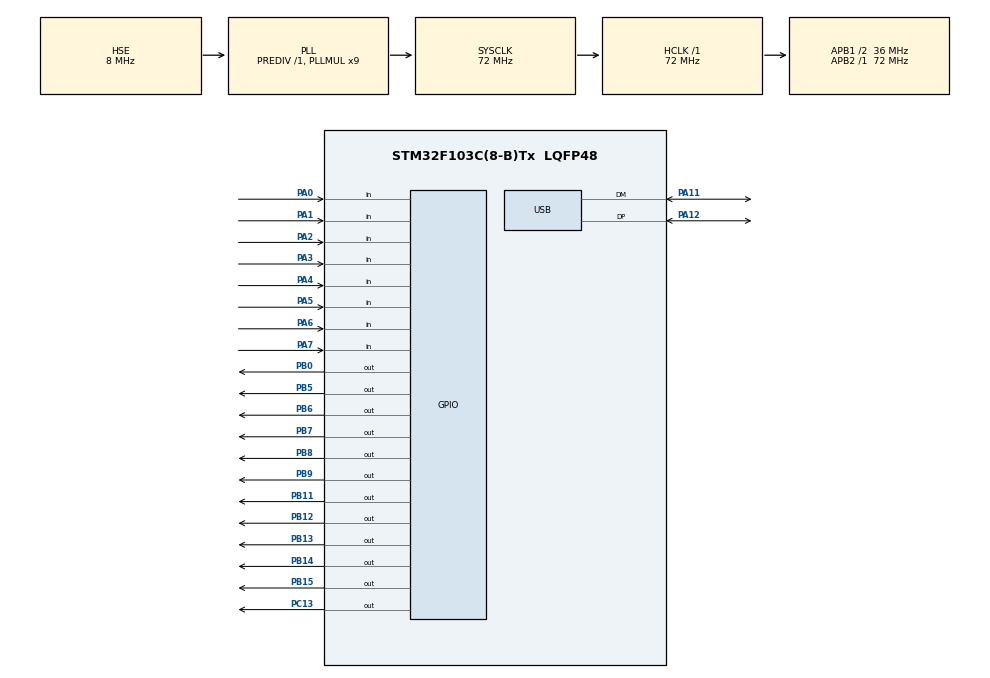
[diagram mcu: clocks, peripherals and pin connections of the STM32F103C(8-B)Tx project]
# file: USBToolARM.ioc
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Mcu.Family=STM32F1
Mcu.Name=STM32F103C(8-B)Tx
Mcu.Package=LQFP48
NVIC.PriorityGroup=NVIC_PRIORITYGROUP_4
NVIC.USB_LP_CAN1_RX0_IRQn=true\:0\:0\:false\:false\:true\:false\:true\:true
PA0-WKUP.Signal=GPIO_Input
PA1.Signal=GPIO_Input
PA11.Mode=Device
PA11.Signal=USB_DM
PA12.Mode=Device
PA12.Signal=USB_DP
PA2.Signal=GPIO_Input
PA3.Signal=GPIO_Input
PA4.Signal=GPIO_Input
PA5.Signal=GPIO_Input
PA6.Signal=GPIO_Input
PA7.Signal=GPIO_Input
PB0.GPIO_Speed=GPIO_SPEED_FREQ_HIGH
PB0.Signal=GPIO_Output
PB11.PinState=GPIO_PIN_SET
PB11.Signal=GPIO_Output
PB12.PinState=GPIO_PIN_RESET
PB12.Signal=GPIO_Output
PB13.Signal=GPIO_Output
PB14.Signal=GPIO_Output
PB15.Signal=GPIO_Output
PB5.GPIO_Speed=GPIO_SPEED_FREQ_HIGH
PB5.Signal=GPIO_Output
PB6.GPIO_PuPd=GPIO_NOPULL
PB6.GPIO_Speed=GPIO_SPEED_FREQ_HIGH
PB6.Signal=GPIO_Output
PB7.GPIO_Speed=GPIO_SPEED_FREQ_HIGH
PB7.Signal=GPIO_Output
PB8.GPIO_Speed=GPIO_SPEED_FREQ_HIGH
PB8.Signal=GPIO_Output
PB9.GPIO_Speed=GPIO_SPEED_FREQ_HIGH
PB9.Signal=GPIO_Output
PC13-TAMPER-RTC.GPIO_ModeDefaultOutputPP=GPIO_MODE_OUTPUT_PP
PC13-TAMPER-RTC.GPIO_PuPd=GPIO_PULLUP
PC13-TAMPER-RTC.Signal=GPIO_Output
PD0-OSC_IN.Mode=HSE-External-Oscillator
PD0-OSC_IN.Signal=RCC_OSC_IN
PD1-OSC_OUT.Mode=HSE-External-Oscillator
PD1-OSC_OUT.Signal=RCC_OSC_OUT
ProjectManager.HeapSize=0x200
ProjectManager.StackSize=0x400
ProjectManager.TargetToolchain=STM32CubeIDE
RCC.AHBFreq_Value=72000000
RCC.APB1CLKDivider=RCC_HCLK_DIV2
RCC.APB1Freq_Value=36000000
RCC.APB1TimFreq_Value=72000000
RCC.APB2Freq_Value=72000000
RCC.APB2TimFreq_Value=72000000
RCC.EnbaleCSS=true
RCC.HCLKFreq_Value=72000000
RCC.PLLMUL=RCC_PLL_MUL9
RCC.PLLSourceVirtual=RCC_PLLSOURCE_HSE
RCC.SYSCLKFreq_VALUE=72000000
RCC.SYSCLKSource=RCC_SYSCLKSOURCE_PLLCLK
RCC.USBFreq_Value=48000000
RCC.USBPrescaler=RCC_USBCLKSOURCE_PLL_DIV1_5
TIM1.Period=0xffff-1
TIM1.Prescaler=72-1
USB_DEVICE.CLASS_NAME_FS=CUSTOM_HID
USB_DEVICE.PID_CUSTOMHID_FS=0x0052
USB_DEVICE.VID=0x04d8
USB_DEVICE.VirtualMode=CustomHid
USB_DEVICE.VirtualModeFS=Custom_Hid_FS
VP_TIM1_VS_ClockSourceINT.Mode=Internal
VP_USB_DEVICE_VS_USB_DEVICE_CUSTOM_HID_FS.Mode=CUSTOM_HID_FS
board=custom

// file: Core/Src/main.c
/* USER CODE BEGIN Header */
/**
  ******************************************************************************
  * @file           : main.c
  * @brief          : Main program body
  ******************************************************************************
  * @attention
  *
  * Copyright (c) 2022 STMicroelectronics.
  * All rights reserved.
  *
  * This software is licensed under terms that can be found in the LICENSE file
  * in the root directory of this software component.
  * If no LICENSE file comes with this software, it is provided AS-IS.
  *
  ******************************************************************************
  */
/* USER CODE END Header */
#include "main.h"
//#include "usb_device.h"

/* USER CODE BEGIN Includes */
#include "timers.h"
#include "PortController.h"
#include "cusb_device.h"
/* USER CODE END Includes */

TIM_HandleTypeDef htim1;

void SystemClock_Config(void);
static void MX_GPIO_Init(void);
static void MX_TIM1_Init(void);

int main(void)
{

  /* MCU Configuration--------------------------------------------------------*/

  /* Reset of all peripherals, Initializes the Flash interface and the Systick. */
  HAL_Init();

  /* Configure the system clock */
  SystemClock_Config();

  /* Initialize all configured peripherals */
  MX_GPIO_Init();
//  MX_USB_DEVICE_Init();
  MX_TIM1_Init();
  /* USER CODE BEGIN 2 */
  CUSTOM_MX_USB_DEVICE_Init();
  Port_init();
//  char buffer[] = {1,2};
//  Port_Write(buffer, 0x333, 2);
//  Port_Write(NULL, 0x333, 1);
//  Port_AsInput();
//  GPIO_PinState test = HAL_GPIO_ReadPin(GPIOA, GPIO_PIN_0);
//
//  if (test)
//  {
//	  Port_AsOutput();
//	  GPIOA->ODR = 0x99;
////	  HAL_GPIO_TogglePin(GPIOA, GPIO_PIN_0);
//
//  }
  /* USER CODE END 2 */

  /* Infinite loop */
  while (1)
  {

    /* USER CODE BEGIN 3 */
//	  HAL_GPIO_TogglePin(GPIOB, GPIO_PIN_0);
//	  delay_us(1);
  }
  /* USER CODE END 3 */
}

void SystemClock_Config(void)
{
  RCC_OscInitTypeDef RCC_OscInitStruct = {0};
  RCC_ClkInitTypeDef RCC_ClkInitStruct = {0};
  RCC_PeriphCLKInitTypeDef PeriphClkInit = {0};

  /** Initializes the RCC Oscillators according to the specified parameters
  * in the RCC_OscInitTypeDef structure.
  */
  RCC_OscInitStruct.OscillatorType = RCC_OSCILLATORTYPE_HSE;
  RCC_OscInitStruct.HSEState = RCC_HSE_ON;
  RCC_OscInitStruct.HSEPredivValue = RCC_HSE_PREDIV_DIV1;
  RCC_OscInitStruct.HSIState = RCC_HSI_ON;
  RCC_OscInitStruct.PLL.PLLState = RCC_PLL_ON;
  RCC_OscInitStruct.PLL.PLLSource = RCC_PLLSOURCE_HSE;
  RCC_OscInitStruct.PLL.PLLMUL = RCC_PLL_MUL9;
  if (HAL_RCC_OscConfig(&RCC_OscInitStruct) != HAL_OK)
  {
    Error_Handler();
  }

  /** Initializes the CPU, AHB and APB buses clocks
  */
  RCC_ClkInitStruct.ClockType = RCC_CLOCKTYPE_HCLK|RCC_CLOCKTYPE_SYSCLK
                              |RCC_CLOCKTYPE_PCLK1|RCC_CLOCKTYPE_PCLK2;
  RCC_ClkInitStruct.SYSCLKSource = RCC_SYSCLKSOURCE_PLLCLK;
  RCC_ClkInitStruct.AHBCLKDivider = RCC_SYSCLK_DIV1;
  RCC_ClkInitStruct.APB1CLKDivider = RCC_HCLK_DIV2;
  RCC_ClkInitStruct.APB2CLKDivider = RCC_HCLK_DIV1;

  if (HAL_RCC_ClockConfig(&RCC_ClkInitStruct, FLASH_LATENCY_2) != HAL_OK)
  {
    Error_Handler();
  }
  PeriphClkInit.PeriphClockSelection = RCC_PERIPHCLK_USB;
  PeriphClkInit.UsbClockSelection = RCC_USBCLKSOURCE_PLL_DIV1_5;
  if (HAL_RCCEx_PeriphCLKConfig(&PeriphClkInit) != HAL_OK)
  {
    Error_Handler();
  }

  /** Enables the Clock Security System
  */
  HAL_RCC_EnableCSS();
}

static void MX_TIM1_Init(void)
{

  TIM_ClockConfigTypeDef sClockSourceConfig = {0};
  TIM_MasterConfigTypeDef sMasterConfig = {0};

  htim1.Instance = TIM1;
  htim1.Init.Prescaler = 72-1;
  htim1.Init.CounterMode = TIM_COUNTERMODE_UP;
  htim1.Init.Period = 0xffff-1;
  htim1.Init.ClockDivision = TIM_CLOCKDIVISION_DIV1;
  htim1.Init.RepetitionCounter = 0;
  htim1.Init.AutoReloadPreload = TIM_AUTORELOAD_PRELOAD_DISABLE;
  if (HAL_TIM_Base_Init(&htim1) != HAL_OK)
  {
    Error_Handler();
  }
  sClockSourceConfig.ClockSource = TIM_CLOCKSOURCE_INTERNAL;
  if (HAL_TIM_ConfigClockSource(&htim1, &sClockSourceConfig) != HAL_OK)
  {
    Error_Handler();
  }
  sMasterConfig.MasterOutputTrigger = TIM_TRGO_RESET;
  sMasterConfig.MasterSlaveMode = TIM_MASTERSLAVEMODE_DISABLE;
  if (HAL_TIMEx_MasterConfigSynchronization(&htim1, &sMasterConfig) != HAL_OK)
  {
    Error_Handler();
  }
  /* USER CODE BEGIN TIM1_Init 2 */
  HAL_TIM_Base_Start(&htim1);
  /* USER CODE END TIM1_Init 2 */

}

static void MX_GPIO_Init(void)
{
  GPIO_InitTypeDef GPIO_InitStruct = {0};

  /* GPIO Ports Clock Enable */
  __HAL_RCC_GPIOC_CLK_ENABLE();
  __HAL_RCC_GPIOD_CLK_ENABLE();
  __HAL_RCC_GPIOA_CLK_ENABLE();
  __HAL_RCC_GPIOB_CLK_ENABLE();

  /*Configure GPIO pin Output Level */
  HAL_GPIO_WritePin(GPIOC, GPIO_PIN_13, GPIO_PIN_RESET);

  /*Configure GPIO pin Output Level */
  HAL_GPIO_WritePin(GPIOB, GPIO_PIN_0|GPIO_PIN_12|GPIO_PIN_13|GPIO_PIN_14
                          |GPIO_PIN_15|GPIO_PIN_5|GPIO_PIN_6|GPIO_PIN_7
                          |GPIO_PIN_8|GPIO_PIN_9, GPIO_PIN_RESET);

  /*Configure GPIO pin Output Level */
  HAL_GPIO_WritePin(GPIOB, GPIO_PIN_11, GPIO_PIN_SET);

  /*Configure GPIO pin : PC13 */
  GPIO_InitStruct.Pin = GPIO_PIN_13;
  GPIO_InitStruct.Mode = GPIO_MODE_OUTPUT_PP;
  GPIO_InitStruct.Pull = GPIO_PULLUP;
  GPIO_InitStruct.Speed = GPIO_SPEED_FREQ_LOW;
  HAL_GPIO_Init(GPIOC, &GPIO_InitStruct);

  /*Configure GPIO pins : PA0 PA1 PA2 PA3
                           PA4 PA5 PA6 PA7 */
  GPIO_InitStruct.Pin = GPIO_PIN_0|GPIO_PIN_1|GPIO_PIN_2|GPIO_PIN_3
                          |GPIO_PIN_4|GPIO_PIN_5|GPIO_PIN_6|GPIO_PIN_7;
  GPIO_InitStruct.Mode = GPIO_MODE_INPUT;
  GPIO_InitStruct.Pull = GPIO_NOPULL;
  HAL_GPIO_Init(GPIOA, &GPIO_InitStruct);

  /*Configure GPIO pins : PB0 PB5 PB6 PB7
                           PB8 PB9 */
  GPIO_InitStruct.Pin = GPIO_PIN_0|GPIO_PIN_5|GPIO_PIN_6|GPIO_PIN_7
                          |GPIO_PIN_8|GPIO_PIN_9;
  GPIO_InitStruct.Mode = GPIO_MODE_OUTPUT_PP;
  GPIO_InitStruct.Pull = GPIO_NOPULL;
  GPIO_InitStruct.Speed = GPIO_SPEED_FREQ_HIGH;
  HAL_GPIO_Init(GPIOB, &GPIO_InitStruct);

  /*Configure GPIO pins : PB11 PB12 PB13 PB14
                           PB15 */
  GPIO_InitStruct.Pin = GPIO_PIN_11|GPIO_PIN_12|GPIO_PIN_13|GPIO_PIN_14
                          |GPIO_PIN_15;
  GPIO_InitStruct.Mode = GPIO_MODE_OUTPUT_PP;
  GPIO_InitStruct.Pull = GPIO_NOPULL;
  GPIO_InitStruct.Speed = GPIO_SPEED_FREQ_LOW;
  HAL_GPIO_Init(GPIOB, &GPIO_InitStruct);

}

void Error_Handler(void)
{
  __disable_irq();
  while (1)
  {
  }
}
